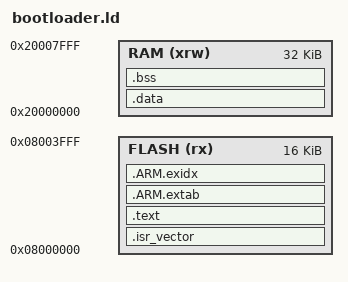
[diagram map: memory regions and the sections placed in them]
/* Bootloader linker script for STM32G431CB */

ENTRY(Reset_Handler)

MEMORY
{
    FLASH (rx) : ORIGIN = 0x08000000, LENGTH = 16K     /* Bootloader region */
    RAM (xrw)  : ORIGIN = 0x20000000, LENGTH = 32K
}

_estack = ORIGIN(RAM) + LENGTH(RAM);

SECTIONS
{
    .isr_vector :
    {
        KEEP(*(.isr_vector))    /* Vector table */
    } > FLASH

    .text :
    {
        *(.text*)
        *(.rodata*)
        KEEP(*(.init))
        KEEP(*(.fini))
    } > FLASH

    .ARM.extab :
    {
        *(.ARM.extab*)
    } > FLASH

    .ARM.exidx :
    {
        *(.ARM.exidx*)
    } > FLASH

    .data : AT (ADDR(.text) + SIZEOF(.text))
    {
        _sdata = .;
        *(.data*)
        _edata = .;
    } > RAM

    .bss :
    {
        _sbss = .;
        *(.bss*)
        *(COMMON)
        _ebss = .;
    } > RAM
}
